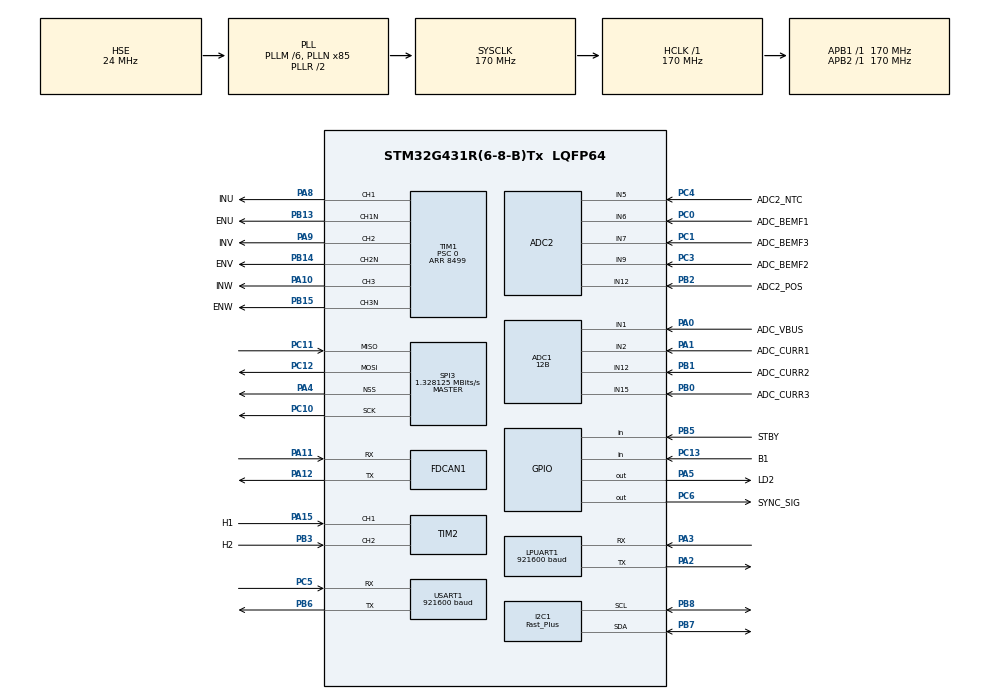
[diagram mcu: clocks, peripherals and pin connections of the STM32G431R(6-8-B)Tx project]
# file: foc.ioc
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ADC1.ClockPrescaler=ADC_CLOCK_SYNC_PCLK_DIV4
ADC1.ContinuousConvMode=ENABLE
ADC1.DiscontinuousConvMode=DISABLE
ADC1.EOCSelection=ADC_EOC_SEQ_CONV
ADC1.EnableInjectedConversion=ENABLE
ADC1.EnableRegularConversion=DISABLE
ADC1.ExternalTrigInjecConv=ADC_EXTERNALTRIGINJEC_T1_TRGO
ADC1.ExternalTrigInjecConvEdge=ADC_EXTERNALTRIGINJECCONV_EDGE_FALLING
ADC1.InjNumberOfConversion=4
ADC1.InjectedChannel-22\#ChannelInjectedConversion=ADC_CHANNEL_1
ADC1.InjectedChannel-23\#ChannelInjectedConversion=ADC_CHANNEL_2
ADC1.InjectedChannel-24\#ChannelInjectedConversion=ADC_CHANNEL_12
ADC1.InjectedChannel-25\#ChannelInjectedConversion=ADC_CHANNEL_15
ADC1.InjectedOffsetNumber-22\#ChannelInjectedConversion=ADC_OFFSET_NONE
ADC1.InjectedOffsetNumber-23\#ChannelInjectedConversion=ADC_OFFSET_NONE
ADC1.InjectedOffsetNumber-24\#ChannelInjectedConversion=ADC_OFFSET_NONE
ADC1.InjectedOffsetNumber-25\#ChannelInjectedConversion=ADC_OFFSET_NONE
ADC1.InjectedRank-22\#ChannelInjectedConversion=1
ADC1.InjectedRank-23\#ChannelInjectedConversion=2
ADC1.InjectedRank-24\#ChannelInjectedConversion=3
ADC1.InjectedRank-25\#ChannelInjectedConversion=4
ADC1.InjectedSamplingTime-22\#ChannelInjectedConversion=ADC_SAMPLETIME_2CYCLES_5
ADC1.InjectedSamplingTime-23\#ChannelInjectedConversion=ADC_SAMPLETIME_2CYCLES_5
ADC1.InjectedSamplingTime-24\#ChannelInjectedConversion=ADC_SAMPLETIME_2CYCLES_5
ADC1.InjectedSamplingTime-25\#ChannelInjectedConversion=ADC_SAMPLETIME_2CYCLES_5
ADC1.Mode=ADC_DUALMODE_INJECSIMULT
ADC1.Overrun=ADC_OVR_DATA_OVERWRITTEN
ADC1.Rank1_Channel=ADC_CHANNEL_1
ADC1.Rank2_Channel=ADC_CHANNEL_2
ADC1.Rank3_Channel=ADC_CHANNEL_12
ADC1.Rank4_Channel=ADC_CHANNEL_15
ADC1.Resolution=ADC_RESOLUTION_12B
ADC1.master=1
ADC2.EnableInjectedConversion=ENABLE
ADC2.EnableRegularConversion=DISABLE
ADC2.InjNumberOfConversion=4
ADC2.InjectedChannel-1\#ChannelInjectedConversion=ADC_CHANNEL_6
ADC2.InjectedChannel-4\#ChannelInjectedConversion=ADC_CHANNEL_9
ADC2.InjectedChannel-5\#ChannelInjectedConversion=ADC_CHANNEL_7
ADC2.InjectedChannel-6\#ChannelInjectedConversion=ADC_CHANNEL_12
ADC2.InjectedOffsetNumber-1\#ChannelInjectedConversion=ADC_OFFSET_NONE
ADC2.InjectedOffsetNumber-4\#ChannelInjectedConversion=ADC_OFFSET_NONE
ADC2.InjectedOffsetNumber-5\#ChannelInjectedConversion=ADC_OFFSET_NONE
ADC2.InjectedOffsetNumber-6\#ChannelInjectedConversion=ADC_OFFSET_NONE
ADC2.InjectedRank-1\#ChannelInjectedConversion=1
ADC2.InjectedRank-4\#ChannelInjectedConversion=2
ADC2.InjectedRank-5\#ChannelInjectedConversion=3
ADC2.InjectedRank-6\#ChannelInjectedConversion=4
ADC2.InjectedSamplingTime-1\#ChannelInjectedConversion=ADC_SAMPLETIME_2CYCLES_5
ADC2.InjectedSamplingTime-4\#ChannelInjectedConversion=ADC_SAMPLETIME_2CYCLES_5
ADC2.InjectedSamplingTime-5\#ChannelInjectedConversion=ADC_SAMPLETIME_2CYCLES_5
ADC2.InjectedSamplingTime-6\#ChannelInjectedConversion=ADC_SAMPLETIME_2CYCLES_5
ADC2.Mode=ADC_DUALMODE_INJECSIMULT
ADC2.Rank4_Channel=ADC_CHANNEL_12
Dma.LPUART1_RX.4.Direction=DMA_PERIPH_TO_MEMORY
Dma.LPUART1_RX.4.EventEnable=DISABLE
Dma.LPUART1_RX.4.Instance=DMA1_Channel5
Dma.LPUART1_RX.4.MemDataAlignment=DMA_MDATAALIGN_BYTE
Dma.LPUART1_RX.4.MemInc=DMA_MINC_ENABLE
Dma.LPUART1_RX.4.Mode=DMA_NORMAL
Dma.LPUART1_RX.4.PeriphDataAlignment=DMA_PDATAALIGN_BYTE
Dma.LPUART1_RX.4.PeriphInc=DMA_PINC_DISABLE
Dma.LPUART1_RX.4.Polarity=HAL_DMAMUX_REQ_GEN_RISING
Dma.LPUART1_RX.4.Priority=DMA_PRIORITY_LOW
Dma.LPUART1_RX.4.RequestNumber=1
Dma.LPUART1_RX.4.SignalID=NONE
Dma.LPUART1_RX.4.SyncEnable=DISABLE
Dma.LPUART1_RX.4.SyncPolarity=HAL_DMAMUX_SYNC_NO_EVENT
Dma.LPUART1_RX.4.SyncRequestNumber=1
Dma.LPUART1_RX.4.SyncSignalID=NONE
Dma.LPUART1_TX.5.Direction=DMA_MEMORY_TO_PERIPH
Dma.LPUART1_TX.5.EventEnable=DISABLE
Dma.LPUART1_TX.5.Instance=DMA1_Channel6
Dma.LPUART1_TX.5.MemDataAlignment=DMA_MDATAALIGN_BYTE
Dma.LPUART1_TX.5.MemInc=DMA_MINC_ENABLE
Dma.LPUART1_TX.5.Mode=DMA_NORMAL
Dma.LPUART1_TX.5.PeriphDataAlignment=DMA_PDATAALIGN_BYTE
Dma.LPUART1_TX.5.PeriphInc=DMA_PINC_DISABLE
Dma.LPUART1_TX.5.Polarity=HAL_DMAMUX_REQ_GEN_RISING
Dma.LPUART1_TX.5.Priority=DMA_PRIORITY_LOW
Dma.LPUART1_TX.5.RequestNumber=1
Dma.LPUART1_TX.5.SignalID=NONE
Dma.LPUART1_TX.5.SyncEnable=DISABLE
Dma.LPUART1_TX.5.SyncPolarity=HAL_DMAMUX_SYNC_NO_EVENT
Dma.LPUART1_TX.5.SyncRequestNumber=1
Dma.LPUART1_TX.5.SyncSignalID=NONE
Dma.Request0=SPI3_RX
Dma.Request1=SPI3_TX
Dma.Request2=USART1_TX
Dma.Request3=USART1_RX
Dma.Request4=LPUART1_RX
Dma.Request5=LPUART1_TX
Dma.SPI3_RX.0.Direction=DMA_PERIPH_TO_MEMORY
Dma.SPI3_RX.0.EventEnable=DISABLE
Dma.SPI3_RX.0.Instance=DMA1_Channel1
Dma.SPI3_RX.0.MemDataAlignment=DMA_MDATAALIGN_BYTE
Dma.SPI3_RX.0.MemInc=DMA_MINC_ENABLE
Dma.SPI3_RX.0.Mode=DMA_NORMAL
Dma.SPI3_RX.0.PeriphDataAlignment=DMA_PDATAALIGN_BYTE
Dma.SPI3_RX.0.PeriphInc=DMA_PINC_DISABLE
Dma.SPI3_RX.0.Polarity=HAL_DMAMUX_REQ_GEN_RISING
Dma.SPI3_RX.0.Priority=DMA_PRIORITY_LOW
Dma.SPI3_RX.0.RequestNumber=1
Dma.SPI3_RX.0.SignalID=NONE
Dma.SPI3_RX.0.SyncEnable=DISABLE
Dma.SPI3_RX.0.SyncPolarity=HAL_DMAMUX_SYNC_NO_EVENT
Dma.SPI3_RX.0.SyncRequestNumber=1
Dma.SPI3_RX.0.SyncSignalID=NONE
Dma.SPI3_TX.1.Direction=DMA_MEMORY_TO_PERIPH
Dma.SPI3_TX.1.EventEnable=DISABLE
Dma.SPI3_TX.1.Instance=DMA1_Channel2
Dma.SPI3_TX.1.MemDataAlignment=DMA_MDATAALIGN_BYTE
Dma.SPI3_TX.1.MemInc=DMA_MINC_ENABLE
Dma.SPI3_TX.1.Mode=DMA_NORMAL
Dma.SPI3_TX.1.PeriphDataAlignment=DMA_PDATAALIGN_BYTE
Dma.SPI3_TX.1.PeriphInc=DMA_PINC_DISABLE
Dma.SPI3_TX.1.Polarity=HAL_DMAMUX_REQ_GEN_RISING
Dma.SPI3_TX.1.Priority=DMA_PRIORITY_LOW
Dma.SPI3_TX.1.RequestNumber=1
Dma.SPI3_TX.1.SignalID=NONE
Dma.SPI3_TX.1.SyncEnable=DISABLE
Dma.SPI3_TX.1.SyncPolarity=HAL_DMAMUX_SYNC_NO_EVENT
Dma.SPI3_TX.1.SyncRequestNumber=1
Dma.SPI3_TX.1.SyncSignalID=NONE
Dma.USART1_RX.3.Direction=DMA_PERIPH_TO_MEMORY
Dma.USART1_RX.3.EventEnable=DISABLE
Dma.USART1_RX.3.Instance=DMA1_Channel4
Dma.USART1_RX.3.MemDataAlignment=DMA_MDATAALIGN_BYTE
Dma.USART1_RX.3.MemInc=DMA_MINC_ENABLE
Dma.USART1_RX.3.Mode=DMA_NORMAL
Dma.USART1_RX.3.PeriphDataAlignment=DMA_PDATAALIGN_BYTE
Dma.USART1_RX.3.PeriphInc=DMA_PINC_DISABLE
Dma.USART1_RX.3.Polarity=HAL_DMAMUX_REQ_GEN_RISING
Dma.USART1_RX.3.Priority=DMA_PRIORITY_LOW
Dma.USART1_RX.3.RequestNumber=1
Dma.USART1_RX.3.SignalID=NONE
Dma.USART1_RX.3.SyncEnable=DISABLE
Dma.USART1_RX.3.SyncPolarity=HAL_DMAMUX_SYNC_NO_EVENT
Dma.USART1_RX.3.SyncRequestNumber=1
Dma.USART1_RX.3.SyncSignalID=NONE
Dma.USART1_TX.2.Direction=DMA_MEMORY_TO_PERIPH
Dma.USART1_TX.2.EventEnable=DISABLE
Dma.USART1_TX.2.Instance=DMA1_Channel3
Dma.USART1_TX.2.MemDataAlignment=DMA_MDATAALIGN_BYTE
Dma.USART1_TX.2.MemInc=DMA_MINC_ENABLE
Dma.USART1_TX.2.Mode=DMA_NORMAL
Dma.USART1_TX.2.PeriphDataAlignment=DMA_PDATAALIGN_BYTE
Dma.USART1_TX.2.PeriphInc=DMA_PINC_DISABLE
Dma.USART1_TX.2.Polarity=HAL_DMAMUX_REQ_GEN_RISING
Dma.USART1_TX.2.Priority=DMA_PRIORITY_LOW
Dma.USART1_TX.2.RequestNumber=1
Dma.USART1_TX.2.SignalID=NONE
Dma.USART1_TX.2.SyncEnable=DISABLE
Dma.USART1_TX.2.SyncPolarity=HAL_DMAMUX_SYNC_NO_EVENT
Dma.USART1_TX.2.SyncRequestNumber=1
Dma.USART1_TX.2.SyncSignalID=NONE
FDCAN1.CalculateBaudRateNominal=200000
FDCAN1.CalculateTimeBitNominal=5000
FDCAN1.CalculateTimeQuantumNominal=100.0
FDCAN1.DataPrescaler=16
FDCAN1.FrameFormat=FDCAN_FRAME_FD_BRS
FDCAN1.Mode=FDCAN_MODE_NORMAL
FDCAN1.NominalPrescaler=17
FDCAN1.NominalTimeSeg1=20
FDCAN1.NominalTimeSeg2=29
I2C1.I2C_Speed_Mode=I2C_Fast_Plus
I2C1.Timing=0x00802172
LPUART1.BaudRate=921600
LPUART1.OverrunDisableParam=UART_ADVFEATURE_OVERRUN_DISABLE
Mcu.Family=STM32G4
Mcu.Name=STM32G431R(6-8-B)Tx
Mcu.Package=LQFP64
Mcu.UserConstants=Fs,20000
NVIC.ADC1_2_IRQn=true\:0\:0\:false\:false\:true\:false\:true\:true\:true
NVIC.DMA1_Channel1_IRQn=true\:0\:0\:false\:false\:true\:true\:false\:true\:true
NVIC.DMA1_Channel2_IRQn=true\:0\:0\:false\:false\:true\:true\:false\:true\:true
NVIC.DMA1_Channel3_IRQn=true\:0\:0\:false\:false\:true\:true\:false\:true\:true
NVIC.DMA1_Channel4_IRQn=true\:0\:0\:false\:false\:true\:true\:false\:true\:true
NVIC.DMA1_Channel5_IRQn=true\:0\:0\:false\:false\:true\:true\:false\:true\:true
NVIC.DMA1_Channel6_IRQn=true\:0\:0\:false\:false\:true\:true\:false\:true\:true
NVIC.I2C1_ER_IRQn=true\:0\:0\:false\:false\:true\:false\:true\:true\:true
NVIC.I2C1_EV_IRQn=true\:0\:0\:false\:false\:true\:false\:true\:true\:true
NVIC.PriorityGroup=NVIC_PRIORITYGROUP_4
NVIC.SPI3_IRQn=true\:0\:0\:false\:false\:true\:false\:true\:true\:true
NVIC.TIM1_CC_IRQn=true\:0\:0\:false\:false\:true\:false\:true\:true\:true
NVIC.TIM1_TRG_COM_TIM17_IRQn=true\:15\:0\:false\:false\:true\:false\:false\:true\:true
NVIC.TIM1_UP_TIM16_IRQn=true\:0\:0\:false\:false\:true\:false\:true\:true\:true
NVIC.TIM7_IRQn=true\:15\:0\:false\:false\:true\:false\:false\:true\:true
NVIC.TimeBase=TIM7_IRQn
NVIC.TimeBaseIP=TIM7
PA0.GPIO_Label=ADC_VBUS
PA0.GPIO_Mode=GPIO_MODE_ANALOG
PA0.GPIO_PuPd=GPIO_NOPULL
PA0.Mode=IN1-Single-Ended
PA0.Signal=ADC1_IN1
PA1.GPIO_Label=ADC_CURR1
PA1.Mode=IN2-Single-Ended
PA1.Signal=ADC1_IN2
PA10.GPIO_Label=INW
PA10.Signal=S_TIM1_CH3
PA11.Mode=FDCAN_Activate
PA11.Signal=FDCAN1_RX
PA12.Mode=FDCAN_Activate
PA12.Signal=FDCAN1_TX
PA13.Mode=Serial_Wire
PA13.Signal=SYS_JTMS-SWDIO
PA14.Mode=Serial_Wire
PA14.Signal=SYS_JTCK-SWCLK
PA15.GPIO_Label=H1
PA15.Signal=S_TIM2_CH1
PA2.Mode=Asynchronous
PA2.Signal=LPUART1_TX
PA3.Mode=Asynchronous
PA3.Signal=LPUART1_RX
PA4.GPIO_PuPd=GPIO_PULLUP
PA4.Mode=NSS_Signal_Hard_Output
PA4.Signal=SPI3_NSS
PA5.GPIO_Label=LD2
PA5.Signal=GPIO_Output
PA8.GPIO_Label=INU
PA8.Signal=S_TIM1_CH1
PA9.GPIO_Label=INV
PA9.Signal=S_TIM1_CH2
PB0.GPIO_Label=ADC_CURR3
PB0.Mode=IN15-Single-Ended
PB0.Signal=ADC1_IN15
PB1.GPIO_Label=ADC_CURR2
PB1.Mode=IN12-Single-Ended
PB1.Signal=ADC1_IN12
PB12.GPIO_Label=EN_FAULT
PB12.Signal=TIM1_BKIN
PB13.GPIO_Label=ENU
PB13.Mode=PWM Generation1 CH1 CH1N
PB13.Signal=TIM1_CH1N
PB14.GPIO_Label=ENV
PB14.Mode=PWM Generation2 CH2 CH2N
PB14.Signal=TIM1_CH2N
PB15.GPIO_Label=ENW
PB15.Mode=PWM Generation3 CH3 CH3N
PB15.Signal=TIM1_CH3N
PB2.GPIO_Label=ADC2_POS
PB2.Mode=IN12-Single-Ended
PB2.Signal=ADC2_IN12
PB3.GPIO_Label=H2
PB3.Signal=S_TIM2_CH2
PB5.GPIO_Label=STBY
PB5.Signal=GPIO_Input
PB6.Mode=Asynchronous
PB6.Signal=USART1_TX
PB7.Mode=I2C
PB7.Signal=I2C1_SDA
PB8-BOOT0.Mode=I2C
PB8-BOOT0.Signal=I2C1_SCL
PC0.GPIO_Label=ADC_BEMF1
PC0.GPIO_Mode=GPIO_MODE_ANALOG
PC0.GPIO_PuPd=GPIO_NOPULL
PC0.Mode=IN6-Single-Ended
PC0.Signal=ADC2_IN6
PC1.GPIO_Label=ADC_BEMF3
PC1.GPIO_Mode=GPIO_MODE_ANALOG
PC1.GPIO_PuPd=GPIO_NOPULL
PC1.Mode=IN7-Single-Ended
PC1.Signal=ADC2_IN7
PC10.GPIO_Speed=GPIO_SPEED_FREQ_MEDIUM
PC10.Mode=Full_Duplex_Master
PC10.Signal=SPI3_SCK
PC11.GPIO_PuPd=GPIO_NOPULL
PC11.GPIO_Speed=GPIO_SPEED_FREQ_MEDIUM
PC11.Mode=Full_Duplex_Master
PC11.Signal=SPI3_MISO
PC12.GPIO_Speed=GPIO_SPEED_FREQ_MEDIUM
PC12.Mode=Full_Duplex_Master
PC12.Signal=SPI3_MOSI
PC13.GPIO_Label=B1
PC13.Signal=GPIO_Input
PC14-OSC32_IN.Mode=LSE-External-Oscillator
PC14-OSC32_IN.Signal=RCC_OSC32_IN
PC15-OSC32_OUT.Mode=LSE-External-Oscillator
PC15-OSC32_OUT.Signal=RCC_OSC32_OUT
PC3.GPIO_Label=ADC_BEMF2
PC3.GPIO_Mode=GPIO_MODE_ANALOG
PC3.GPIO_PuPd=GPIO_NOPULL
PC3.Mode=IN9-Single-Ended
PC3.Signal=ADC2_IN9
PC4.GPIO_Label=ADC2_NTC
PC4.Mode=IN5-Single-Ended
PC4.Signal=ADC2_IN5
PC5.Mode=Asynchronous
PC5.Signal=USART1_RX
PC6.GPIO_Label=SYNC_SIG
PC6.GPIO_Speed=GPIO_SPEED_FREQ_VERY_HIGH
PC6.Signal=GPIO_Output
PF0-OSC_IN.Mode=HSE-External-Oscillator
PF0-OSC_IN.Signal=RCC_OSC_IN
PF1-OSC_OUT.Mode=HSE-External-Oscillator
PF1-OSC_OUT.Signal=RCC_OSC_OUT
ProjectManager.HeapSize=0x200
ProjectManager.StackSize=0x400
ProjectManager.TargetToolchain=Makefile
RCC.ADC12Freq_Value=170000000
RCC.AHBFreq_Value=170000000
RCC.APB1Freq_Value=170000000
RCC.APB1TimFreq_Value=170000000
RCC.APB2Freq_Value=170000000
RCC.APB2TimFreq_Value=170000000
RCC.CortexFreq_Value=170000000
RCC.EXTERNAL_CLOCK_VALUE=12288000
RCC.HCLKFreq_Value=170000000
RCC.HSE_VALUE=24000000
RCC.HSI48_VALUE=48000000
RCC.HSI_VALUE=16000000
RCC.PLLM=RCC_PLLM_DIV6
RCC.PLLN=85
RCC.PLLSourceVirtual=RCC_PLLSOURCE_HSE
RCC.SYSCLKFreq_VALUE=170000000
RCC.SYSCLKSource=RCC_SYSCLKSOURCE_PLLCLK
RCC.USBFreq_Value=170000000
RCC.VCOOutputFreq_Value=340000000
SH.S_TIM1_CH1.0=TIM1_CH1,PWM Generation1 CH1 CH1N
SH.S_TIM1_CH2.0=TIM1_CH2,PWM Generation2 CH2 CH2N
SH.S_TIM1_CH3.0=TIM1_CH3,PWM Generation3 CH3 CH3N
SH.S_TIM2_CH1.0=TIM2_CH1,Encoder_Interface_w_index_CH1_CH2_remapETR_TIM2
SH.S_TIM2_CH2.0=TIM2_CH2,Encoder_Interface_w_index_CH1_CH2_remapETR_TIM2
SPI3.BaudRatePrescaler=SPI_BAUDRATEPRESCALER_128
SPI3.CLKPhase=SPI_PHASE_2EDGE
SPI3.CLKPolarity=SPI_POLARITY_HIGH
SPI3.CalculateBaudRate=1.328125 MBits/s
SPI3.DataSize=SPI_DATASIZE_8BIT
SPI3.Direction=SPI_DIRECTION_2LINES
SPI3.Mode=SPI_MODE_MASTER
SPI3.VirtualNSS=VM_NSSHARD
SPI3.VirtualType=VM_MASTER
STMicroelectronics.X-CUBE-AZRTOS-G4.1.0.0.TX_TIMER_TICKS_PER_SECOND=1000
STMicroelectronics.X-CUBE-AZRTOS-G4.1.0.0.ThreadXCcRTOSJjThreadXJjCore=true
STMicroelectronics.X-CUBE-AZRTOS-G4.1.0.0.ThreadXCcRTOSJjThreadXJjPerformanceInfo=true
STMicroelectronics.X-CUBE-AZRTOS-G4.1.0.0.ThreadXCcRTOSJjThreadXJjTraceXOosupport=true
STMicroelectronics.X-CUBE-AZRTOS-G4.1.0.0_IsAnAzureRtosMw=true
TIM1.AsymmetricalDeadTime=ENABLE
TIM1.Channel-PWM\ Generation1\ CH1\ CH1N=TIM_CHANNEL_1
TIM1.Channel-PWM\ Generation2\ CH2\ CH2N=TIM_CHANNEL_2
TIM1.Channel-PWM\ Generation3\ CH3\ CH3N=TIM_CHANNEL_3
TIM1.Channel-PWM\ Generation4\ No\ Output=TIM_CHANNEL_4
TIM1.CounterMode=TIM_COUNTERMODE_CENTERALIGNED2
TIM1.DeadTime=10
TIM1.Dithering=Disable
TIM1.FallingDeadTime=5
TIM1.OCMode_PWM-PWM\ Generation1\ CH1\ CH1N=TIM_OCMODE_PWM1
TIM1.OCMode_PWM-PWM\ Generation2\ CH2\ CH2N=TIM_OCMODE_PWM1
TIM1.OCMode_PWM-PWM\ Generation3\ CH3\ CH3N=TIM_OCMODE_PWM1
TIM1.OCNPolarity_1=TIM_OCNPOLARITY_HIGH
TIM1.OCNPolarity_2=TIM_OCNPOLARITY_HIGH
TIM1.OCNPolarity_3=TIM_OCNPOLARITY_HIGH
TIM1.OCPolarity_1=TIM_OCPOLARITY_HIGH
TIM1.OCPolarity_2=TIM_OCPOLARITY_HIGH
TIM1.OCPolarity_3=TIM_OCPOLARITY_HIGH
TIM1.PeriodNoDither=8499
TIM1.Prescaler=0
TIM1.TIM_MasterOutputTrigger=TIM_TRGO_OC4REF
TIM1.TIM_MasterOutputTrigger2=TIM_TRGO2_UPDATE
TIM16.PeriodNoDither=999
TIM16.Prescaler=169
TIM16.RepetitionCounter=0
USART1.BaudRate=921600
USART1.OverrunDisableParam=ADVFEATURE_OVERRUN_DISABLE
USART1.VirtualMode-Asynchronous=VM_ASYNC
VP_CORDIC_VS_CORDIC.Mode=CORDIC_Activate
VP_STMicroelectronics.X-CUBE-AZRTOS-G4_VS_RTOSJjThreadX_6.1.8_1.0.0.Mode=RTOSJjThreadX
VP_SYS_VS_DBSignals.Mode=DisableDeadBatterySignals
VP_SYS_VS_tim7.Mode=TIM7
VP_TIM16_VS_ClockSourceINT.Mode=Enable_Timer
VP_TIM1_VS_ClockSourceINT.Mode=Internal
VP_TIM1_VS_no_output4.Mode=PWM Generation4 No Output
board=custom

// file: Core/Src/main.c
/* USER CODE BEGIN Header */
/**
 ******************************************************************************
 * @file           : main.c
 * @brief          : Main program body
 ******************************************************************************
 * @attention
 *
 * Copyright (c) 2022 STMicroelectronics.
 * All rights reserved.
 *
 * This software is licensed under terms that can be found in the LICENSE file
 * in the root directory of this software component.
 * If no LICENSE file comes with this software, it is provided AS-IS.
 *
 ******************************************************************************
 */
/* USER CODE END Header */
#include "app_threadx.h"
#include "main.h"
#include "adc.h"
#include "cordic.h"
#include "dma.h"
#include "fdcan.h"
#include "i2c.h"
#include "usart.h"
#include "spi.h"
#include "tim.h"
#include "gpio.h"

/* USER CODE BEGIN Includes */
#include "rtt/SEGGER_RTT.h"
/* USER CODE END Includes */

void SystemClock_Config(void);

int main(void)
{

  /* MCU Configuration--------------------------------------------------------*/

  /* Reset of all peripherals, Initializes the Flash interface and the Systick. */
  HAL_Init();

  /* Configure the system clock */
  SystemClock_Config();

  /* Initialize all configured peripherals */
  MX_GPIO_Init();
  MX_DMA_Init();
  MX_ADC1_Init();
  MX_CORDIC_Init();
  MX_TIM1_Init();
  MX_ADC2_Init();
  MX_TIM2_Init();
  MX_USART1_UART_Init();
  MX_I2C1_Init();
  MX_TIM16_Init();
  MX_SPI3_Init();
  MX_FDCAN1_Init();
  MX_LPUART1_UART_Init();
  /* USER CODE BEGIN 2 */
    SEGGER_RTT_Init();
  /* USER CODE END 2 */

  MX_ThreadX_Init();

  /* We should never get here as control is now taken by the scheduler */
  /* Infinite loop */
    while (1) {

    }
}

void SystemClock_Config(void)
{
  RCC_OscInitTypeDef RCC_OscInitStruct = {0};
  RCC_ClkInitTypeDef RCC_ClkInitStruct = {0};

  /** Configure the main internal regulator output voltage
  */
  HAL_PWREx_ControlVoltageScaling(PWR_REGULATOR_VOLTAGE_SCALE1_BOOST);

  /** Initializes the RCC Oscillators according to the specified parameters
  * in the RCC_OscInitTypeDef structure.
  */
  RCC_OscInitStruct.OscillatorType = RCC_OSCILLATORTYPE_HSE;
  RCC_OscInitStruct.HSEState = RCC_HSE_ON;
  RCC_OscInitStruct.PLL.PLLState = RCC_PLL_ON;
  RCC_OscInitStruct.PLL.PLLSource = RCC_PLLSOURCE_HSE;
  RCC_OscInitStruct.PLL.PLLM = RCC_PLLM_DIV6;
  RCC_OscInitStruct.PLL.PLLN = 85;
  RCC_OscInitStruct.PLL.PLLP = RCC_PLLP_DIV2;
  RCC_OscInitStruct.PLL.PLLQ = RCC_PLLQ_DIV2;
  RCC_OscInitStruct.PLL.PLLR = RCC_PLLR_DIV2;
  if (HAL_RCC_OscConfig(&RCC_OscInitStruct) != HAL_OK)
  {
    Error_Handler();
  }

  /** Initializes the CPU, AHB and APB buses clocks
  */
  RCC_ClkInitStruct.ClockType = RCC_CLOCKTYPE_HCLK|RCC_CLOCKTYPE_SYSCLK
                              |RCC_CLOCKTYPE_PCLK1|RCC_CLOCKTYPE_PCLK2;
  RCC_ClkInitStruct.SYSCLKSource = RCC_SYSCLKSOURCE_PLLCLK;
  RCC_ClkInitStruct.AHBCLKDivider = RCC_SYSCLK_DIV1;
  RCC_ClkInitStruct.APB1CLKDivider = RCC_HCLK_DIV1;
  RCC_ClkInitStruct.APB2CLKDivider = RCC_HCLK_DIV1;

  if (HAL_RCC_ClockConfig(&RCC_ClkInitStruct, FLASH_LATENCY_4) != HAL_OK)
  {
    Error_Handler();
  }
}

void HAL_TIM_PeriodElapsedCallback(TIM_HandleTypeDef *htim)
{
  if (htim->Instance == TIM7) {
    HAL_IncTick();
  }
}

void Error_Handler(void)
{
    __disable_irq();
    while (1) {
    }
}
